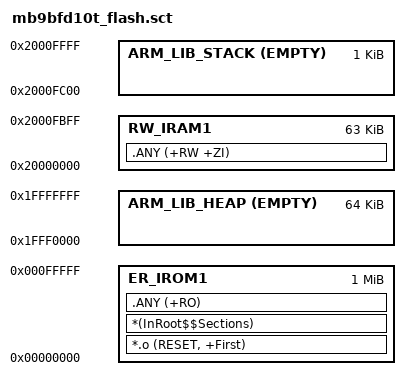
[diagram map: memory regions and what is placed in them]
;********************************************************************
;* MB9BFD10T linker scatter file (running code from internal FLASH) *
;********************************************************************

LR_IROM1 0x00000000 0x100000
{
   ER_IROM1 0x00000000 0x100000
   {
      *.o (RESET, +First)
      *(InRoot$$Sections)
      .ANY (+RO)
   }
   
   RW_IRAM1 0x20000000 0xFC00
   { 
      .ANY (+RW +ZI)
   }
   
   ARM_LIB_STACK 0x20010000 EMPTY -0x400
   {
   }
   
   ARM_LIB_HEAP 0x1FFF0000 EMPTY 0x10000
   {
   }
}
